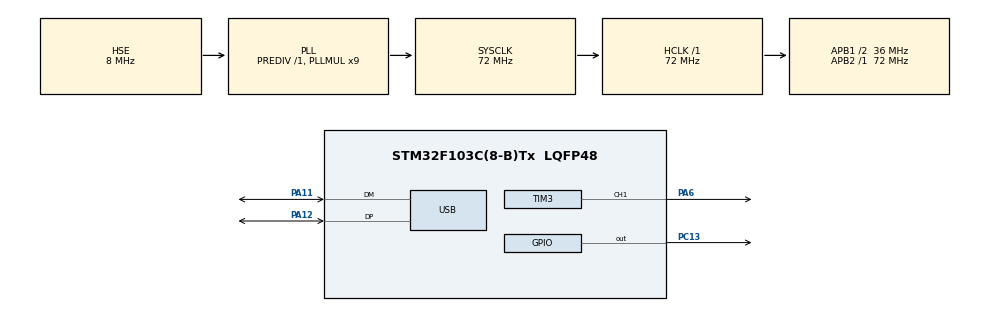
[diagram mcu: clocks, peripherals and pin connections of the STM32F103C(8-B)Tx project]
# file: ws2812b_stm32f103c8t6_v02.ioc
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Dma.Request0=TIM3_CH1/TRIG
Dma.TIM3_CH1/TRIG.0.Direction=DMA_MEMORY_TO_PERIPH
Dma.TIM3_CH1/TRIG.0.Instance=DMA1_Channel6
Dma.TIM3_CH1/TRIG.0.MemDataAlignment=DMA_MDATAALIGN_BYTE
Dma.TIM3_CH1/TRIG.0.MemInc=DMA_MINC_ENABLE
Dma.TIM3_CH1/TRIG.0.Mode=DMA_NORMAL
Dma.TIM3_CH1/TRIG.0.PeriphDataAlignment=DMA_PDATAALIGN_HALFWORD
Dma.TIM3_CH1/TRIG.0.PeriphInc=DMA_PINC_DISABLE
Dma.TIM3_CH1/TRIG.0.Priority=DMA_PRIORITY_LOW
Mcu.Family=STM32F1
Mcu.Name=STM32F103C(8-B)Tx
Mcu.Package=LQFP48
NVIC.DMA1_Channel6_IRQn=true\:0\:0\:false\:false\:true\:false\:true
NVIC.PriorityGroup=NVIC_PRIORITYGROUP_4
NVIC.USB_LP_CAN1_RX0_IRQn=true\:0\:0\:false\:false\:true\:false\:true
PA11.Mode=Device
PA11.Signal=USB_DM
PA12.Mode=Device
PA12.Signal=USB_DP
PA13.Mode=Serial_Wire
PA13.Signal=SYS_JTMS-SWDIO
PA14.Mode=Serial_Wire
PA14.Signal=SYS_JTCK-SWCLK
PA6.GPIO_Speed=GPIO_SPEED_FREQ_HIGH
PA6.Signal=S_TIM3_CH1
PC13-TAMPER-RTC.Signal=GPIO_Output
PC14-OSC32_IN.Mode=LSE-External-Oscillator
PC14-OSC32_IN.Signal=RCC_OSC32_IN
PC15-OSC32_OUT.Mode=LSE-External-Oscillator
PC15-OSC32_OUT.Signal=RCC_OSC32_OUT
PD0-OSC_IN.Mode=HSE-External-Oscillator
PD0-OSC_IN.Signal=RCC_OSC_IN
PD1-OSC_OUT.Mode=HSE-External-Oscillator
PD1-OSC_OUT.Signal=RCC_OSC_OUT
ProjectManager.HeapSize=0x200
ProjectManager.StackSize=0x400
ProjectManager.TargetToolchain=STM32CubeIDE
RCC.AHBFreq_Value=72000000
RCC.APB1CLKDivider=RCC_HCLK_DIV2
RCC.APB1Freq_Value=36000000
RCC.APB1TimFreq_Value=72000000
RCC.APB2Freq_Value=72000000
RCC.APB2TimFreq_Value=72000000
RCC.HCLKFreq_Value=72000000
RCC.PLLMUL=RCC_PLL_MUL9
RCC.SYSCLKFreq_VALUE=72000000
RCC.SYSCLKSource=RCC_SYSCLKSOURCE_PLLCLK
RCC.USBFreq_Value=48000000
RCC.USBPrescaler=RCC_USBCLKSOURCE_PLL_DIV1_5
SH.S_TIM3_CH1.0=TIM3_CH1,PWM Generation1 CH1
TIM3.Channel-PWM\ Generation1\ CH1=TIM_CHANNEL_1
TIM3.Period=89
USB_DEVICE.CLASS_NAME_FS=CDC
USB_DEVICE.VirtualMode=Cdc
USB_DEVICE.VirtualModeFS=Cdc_FS
VP_TIM3_VS_ClockSourceINT.Mode=Internal
VP_USB_DEVICE_VS_USB_DEVICE_CDC_FS.Mode=CDC_FS
board=custom

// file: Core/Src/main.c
/* USER CODE BEGIN Header */
/**
  ******************************************************************************
  * @file           : main.c
  * @brief          : Main program body
  ******************************************************************************
  * @attention
  *
  * <h2><center>&copy; Copyright (c) 2021 STMicroelectronics.
  * All rights reserved.</center></h2>
  *
  * This software component is licensed by ST under Ultimate Liberty license
  * SLA0044, the "License"; You may not use this file except in compliance with
  * the License. You may obtain a copy of the License at:
  *                             www.st.com/SLA0044
  *
  ******************************************************************************
  */
/* USER CODE END Header */
#include "main.h"
#include "usb_device.h"

/* USER CODE BEGIN Includes */

#include <stdlib.h>

/* USER CODE END Includes */

/* USER CODE BEGIN PD */

//#define RESET_LENGTH 36
//#define STATE_LOW    26
//#define STATE_HIGH   59
//#define STATE_100    90

/* USER CODE END PD */

//TIM_HandleTypeDef htim3;
DMA_HandleTypeDef hdma_tim3_ch1_trig;

/* USER CODE BEGIN PV */

#include "ws2812b.h"

/* USER CODE END PV */

void SystemClock_Config(void);
static void MX_GPIO_Init(void);
static void MX_DMA_Init(void);
static void MX_TIM3_Init(void);

int main(void)
{

  /* MCU Configuration--------------------------------------------------------*/

  /* Reset of all peripherals, Initializes the Flash interface and the Systick. */
  HAL_Init();

  /* Configure the system clock */
  SystemClock_Config();

  /* Initialize all configured peripherals */
  MX_GPIO_Init();
  MX_DMA_Init();
  MX_TIM3_Init();
  MX_USB_DEVICE_Init();
  /* USER CODE BEGIN 2 */

//  __TIM3_CLK_ENABLE();
//
//  HAL_TIM_Base_Start(&htim3);
//
//  uint8_t test[RESET_LENGTH + 8 * 24 + 1] = {0};
//
//  // Zerowanie kolorów wszystkich diod
//  for (int i = 0; i < 8 * 24; i++)
//    test[RESET_LENGTH + i] = STATE_LOW;
//
//  // Włącz 1-sza zeilona, 2-ga czerwona, 3-cia niebieska
//  test[ RESET_LENGTH + 0 ] = STATE_HIGH;
//  test[ RESET_LENGTH + 24 + 8 ] = STATE_HIGH;
//  test[ RESET_LENGTH + 48 + 16 ] = STATE_HIGH;
//
//  // Stan wysoki na końcu
//  test[RESET_LENGTH + 8 * 24] = STATE_100;
//
//  HAL_TIM_PWM_Start_DMA(&htim3, TIM_CHANNEL_1, &test, sizeof(test));

  /* USER CODE END 2 */

  /* Infinite loop */
  /* USER CODE BEGIN WHILE */

  ws2812b_init();

  srand( (unsigned) time( NULL ));

  while (1)
  {
//	uint8_t r = rand();
//	uint8_t g = rand();
//	uint8_t b = rand();

	uint16_t volume = 128; // max 256
	uint8_t r = gamma8[ rand() % volume ];
	uint8_t g = gamma8[ rand() % volume ];
	uint8_t b = gamma8[ rand() % volume ];

	for( int led = 0; led < LED_N; led++ ) {
	  ws2812b_set_color( led, r, g, b );
	  ws2812b_update();
	  HAL_Delay( 100 );
	}

    /* USER CODE END WHILE */

  }
}

void SystemClock_Config(void)
{
  RCC_OscInitTypeDef RCC_OscInitStruct = {0};
  RCC_ClkInitTypeDef RCC_ClkInitStruct = {0};
  RCC_PeriphCLKInitTypeDef PeriphClkInit = {0};

  /** Initializes the RCC Oscillators according to the specified parameters
  * in the RCC_OscInitTypeDef structure.
  */
  RCC_OscInitStruct.OscillatorType = RCC_OSCILLATORTYPE_HSE;
  RCC_OscInitStruct.HSEState = RCC_HSE_ON;
  RCC_OscInitStruct.HSEPredivValue = RCC_HSE_PREDIV_DIV1;
  RCC_OscInitStruct.HSIState = RCC_HSI_ON;
  RCC_OscInitStruct.PLL.PLLState = RCC_PLL_ON;
  RCC_OscInitStruct.PLL.PLLSource = RCC_PLLSOURCE_HSE;
  RCC_OscInitStruct.PLL.PLLMUL = RCC_PLL_MUL9;
  if (HAL_RCC_OscConfig(&RCC_OscInitStruct) != HAL_OK)
  {
    Error_Handler();
  }
  /** Initializes the CPU, AHB and APB buses clocks
  */
  RCC_ClkInitStruct.ClockType = RCC_CLOCKTYPE_HCLK|RCC_CLOCKTYPE_SYSCLK
                              |RCC_CLOCKTYPE_PCLK1|RCC_CLOCKTYPE_PCLK2;
  RCC_ClkInitStruct.SYSCLKSource = RCC_SYSCLKSOURCE_PLLCLK;
  RCC_ClkInitStruct.AHBCLKDivider = RCC_SYSCLK_DIV1;
  RCC_ClkInitStruct.APB1CLKDivider = RCC_HCLK_DIV2;
  RCC_ClkInitStruct.APB2CLKDivider = RCC_HCLK_DIV1;

  if (HAL_RCC_ClockConfig(&RCC_ClkInitStruct, FLASH_LATENCY_2) != HAL_OK)
  {
    Error_Handler();
  }
  PeriphClkInit.PeriphClockSelection = RCC_PERIPHCLK_USB;
  PeriphClkInit.UsbClockSelection = RCC_USBCLKSOURCE_PLL_DIV1_5;
  if (HAL_RCCEx_PeriphCLKConfig(&PeriphClkInit) != HAL_OK)
  {
    Error_Handler();
  }
}

static void MX_TIM3_Init(void)
{

  TIM_ClockConfigTypeDef sClockSourceConfig = {0};
  TIM_MasterConfigTypeDef sMasterConfig = {0};
  TIM_OC_InitTypeDef sConfigOC = {0};

  htim3.Instance = TIM3;
  htim3.Init.Prescaler = 0;
  htim3.Init.CounterMode = TIM_COUNTERMODE_UP;
  htim3.Init.Period = 89;
  htim3.Init.ClockDivision = TIM_CLOCKDIVISION_DIV1;
  htim3.Init.AutoReloadPreload = TIM_AUTORELOAD_PRELOAD_DISABLE;
  if (HAL_TIM_Base_Init(&htim3) != HAL_OK)
  {
    Error_Handler();
  }
  sClockSourceConfig.ClockSource = TIM_CLOCKSOURCE_INTERNAL;
  if (HAL_TIM_ConfigClockSource(&htim3, &sClockSourceConfig) != HAL_OK)
  {
    Error_Handler();
  }
  if (HAL_TIM_PWM_Init(&htim3) != HAL_OK)
  {
    Error_Handler();
  }
  sMasterConfig.MasterOutputTrigger = TIM_TRGO_RESET;
  sMasterConfig.MasterSlaveMode = TIM_MASTERSLAVEMODE_DISABLE;
  if (HAL_TIMEx_MasterConfigSynchronization(&htim3, &sMasterConfig) != HAL_OK)
  {
    Error_Handler();
  }
  sConfigOC.OCMode = TIM_OCMODE_PWM1;
  sConfigOC.Pulse = 0;
  sConfigOC.OCPolarity = TIM_OCPOLARITY_HIGH;
  sConfigOC.OCFastMode = TIM_OCFAST_DISABLE;
  if (HAL_TIM_PWM_ConfigChannel(&htim3, &sConfigOC, TIM_CHANNEL_1) != HAL_OK)
  {
    Error_Handler();
  }
  HAL_TIM_MspPostInit(&htim3);

}

static void MX_DMA_Init(void)
{

  /* DMA controller clock enable */
  __HAL_RCC_DMA1_CLK_ENABLE();

  /* DMA interrupt init */
  /* DMA1_Channel6_IRQn interrupt configuration */
  HAL_NVIC_SetPriority(DMA1_Channel6_IRQn, 0, 0);
  HAL_NVIC_EnableIRQ(DMA1_Channel6_IRQn);

}

static void MX_GPIO_Init(void)
{
  GPIO_InitTypeDef GPIO_InitStruct = {0};

  /* GPIO Ports Clock Enable */
  __HAL_RCC_GPIOC_CLK_ENABLE();
  __HAL_RCC_GPIOD_CLK_ENABLE();
  __HAL_RCC_GPIOA_CLK_ENABLE();

  /*Configure GPIO pin Output Level */
  HAL_GPIO_WritePin(GPIOC, GPIO_PIN_13, GPIO_PIN_RESET);

  /*Configure GPIO pin : PC13 */
  GPIO_InitStruct.Pin = GPIO_PIN_13;
  GPIO_InitStruct.Mode = GPIO_MODE_OUTPUT_PP;
  GPIO_InitStruct.Pull = GPIO_NOPULL;
  GPIO_InitStruct.Speed = GPIO_SPEED_FREQ_LOW;
  HAL_GPIO_Init(GPIOC, &GPIO_InitStruct);

}

void Error_Handler(void)
{
}

/************************ (C) COPYRIGHT STMicroelectronics *****END OF FILE****/
